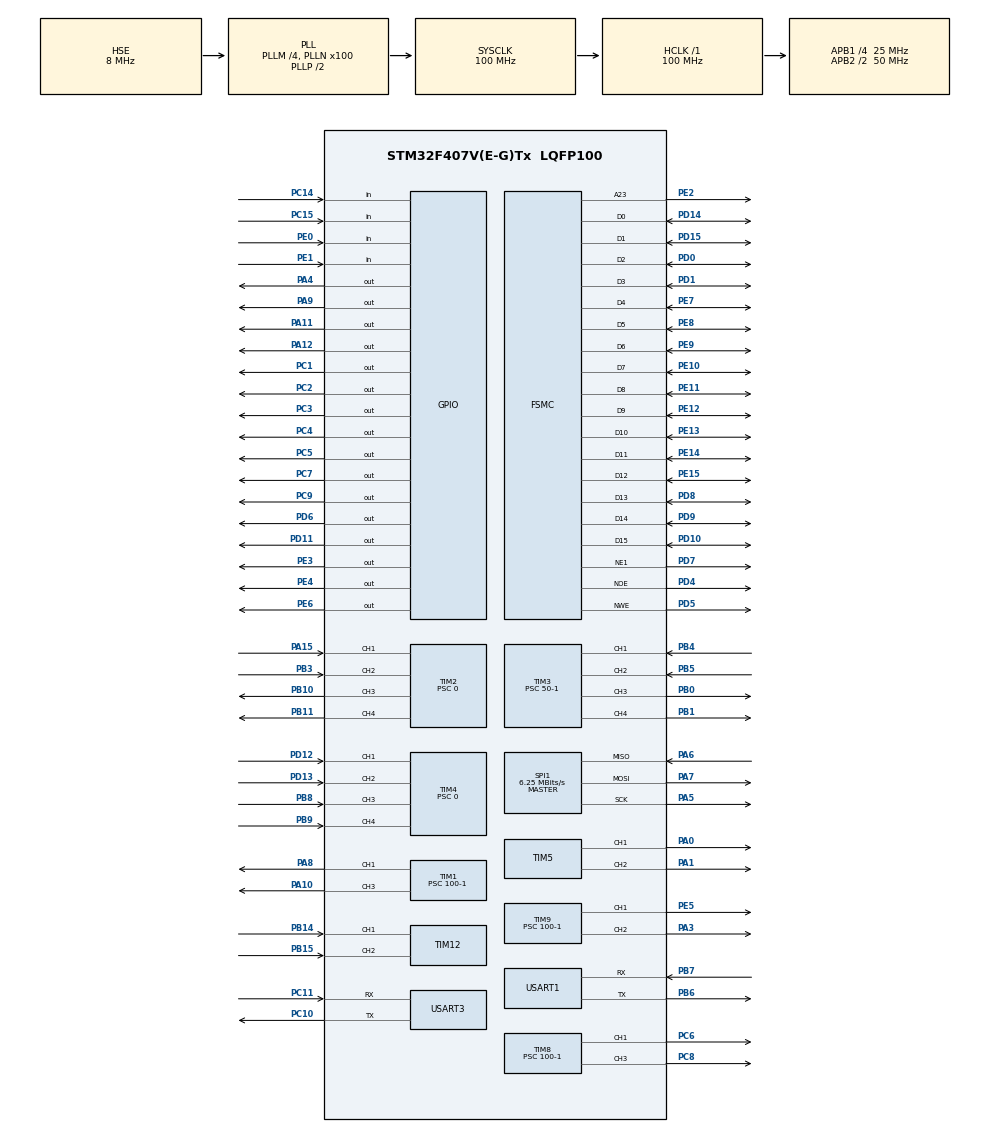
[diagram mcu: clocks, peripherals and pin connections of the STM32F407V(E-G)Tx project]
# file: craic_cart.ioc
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Dma.Request0=USART3_RX
Dma.Request1=USART1_RX
Dma.USART1_RX.1.Direction=DMA_PERIPH_TO_MEMORY
Dma.USART1_RX.1.FIFOMode=DMA_FIFOMODE_DISABLE
Dma.USART1_RX.1.Instance=DMA2_Stream2
Dma.USART1_RX.1.MemDataAlignment=DMA_MDATAALIGN_BYTE
Dma.USART1_RX.1.MemInc=DMA_MINC_ENABLE
Dma.USART1_RX.1.Mode=DMA_NORMAL
Dma.USART1_RX.1.PeriphDataAlignment=DMA_PDATAALIGN_BYTE
Dma.USART1_RX.1.PeriphInc=DMA_PINC_DISABLE
Dma.USART1_RX.1.Priority=DMA_PRIORITY_LOW
Dma.USART3_RX.0.Direction=DMA_PERIPH_TO_MEMORY
Dma.USART3_RX.0.FIFOMode=DMA_FIFOMODE_DISABLE
Dma.USART3_RX.0.Instance=DMA1_Stream1
Dma.USART3_RX.0.MemDataAlignment=DMA_MDATAALIGN_BYTE
Dma.USART3_RX.0.MemInc=DMA_MINC_ENABLE
Dma.USART3_RX.0.Mode=DMA_NORMAL
Dma.USART3_RX.0.PeriphDataAlignment=DMA_PDATAALIGN_BYTE
Dma.USART3_RX.0.PeriphInc=DMA_PINC_DISABLE
Dma.USART3_RX.0.Priority=DMA_PRIORITY_LOW
Mcu.Family=STM32F4
Mcu.Name=STM32F407V(E-G)Tx
Mcu.Package=LQFP100
NVIC.DMA1_Stream1_IRQn=true\:0\:0\:false\:false\:true\:false\:true
NVIC.DMA2_Stream2_IRQn=true\:0\:0\:false\:false\:true\:false\:true
NVIC.PriorityGroup=NVIC_PRIORITYGROUP_4
NVIC.TIM1_TRG_COM_TIM11_IRQn=true\:0\:0\:false\:false\:true\:true\:true
NVIC.TIM1_UP_TIM10_IRQn=true\:0\:0\:false\:false\:true\:true\:true
NVIC.TIM2_IRQn=true\:0\:0\:false\:false\:true\:true\:true
NVIC.TIM3_IRQn=true\:0\:0\:false\:false\:true\:true\:true
NVIC.TIM4_IRQn=true\:0\:0\:false\:false\:true\:true\:true
NVIC.TIM6_DAC_IRQn=true\:0\:0\:false\:false\:true\:true\:true
NVIC.TIM7_IRQn=true\:1\:0\:true\:false\:true\:true\:true
NVIC.TIM8_BRK_TIM12_IRQn=true\:0\:0\:false\:false\:true\:true\:true
NVIC.TIM8_TRG_COM_TIM14_IRQn=true\:2\:0\:true\:false\:true\:true\:true
NVIC.TIM8_UP_TIM13_IRQn=true\:1\:0\:true\:false\:true\:true\:true
NVIC.USART1_IRQn=true\:0\:0\:false\:false\:true\:true\:true
NVIC.USART3_IRQn=true\:0\:0\:false\:false\:true\:true\:true
PA0-WKUP.Signal=S_TIM5_CH1
PA1.Signal=S_TIM5_CH2
PA10.Signal=S_TIM1_CH3
PA11.Signal=GPIO_Output
PA12.GPIO_ModeDefaultOutputPP=GPIO_MODE_OUTPUT_PP
PA12.GPIO_PuPd=GPIO_PULLDOWN
PA12.GPIO_Speed=GPIO_SPEED_FREQ_VERY_HIGH
PA12.PinState=GPIO_PIN_RESET
PA12.Signal=GPIO_Output
PA13.Mode=Serial_Wire
PA13.Signal=SYS_JTMS-SWDIO
PA14.Mode=Serial_Wire
PA14.Signal=SYS_JTCK-SWCLK
PA15.Signal=S_TIM2_CH1_ETR
PA3.Signal=S_TIM9_CH2
PA4.Signal=GPIO_Output
PA5.Mode=Full_Duplex_Master
PA5.Signal=SPI1_SCK
PA6.Mode=Full_Duplex_Master
PA6.Signal=SPI1_MISO
PA7.Mode=Full_Duplex_Master
PA7.Signal=SPI1_MOSI
PA8.Signal=S_TIM1_CH1
PA9.Signal=GPIO_Output
PB0.Signal=S_TIM3_CH3
PB1.Signal=S_TIM3_CH4
PB10.Signal=S_TIM2_CH3
PB11.Signal=S_TIM2_CH4
PB14.Signal=S_TIM12_CH1
PB15.Signal=S_TIM12_CH2
PB3.Signal=S_TIM2_CH2
PB4.Signal=S_TIM3_CH1
PB5.Signal=S_TIM3_CH2
PB6.Mode=Asynchronous
PB6.Signal=USART1_TX
PB7.Mode=Asynchronous
PB7.Signal=USART1_RX
PB8.Signal=S_TIM4_CH3
PB9.Signal=S_TIM4_CH4
PC1.Signal=GPIO_Output
PC10.Mode=Asynchronous
PC10.Signal=USART3_TX
PC11.Mode=Asynchronous
PC11.Signal=USART3_RX
PC14-OSC32_IN.GPIO_Mode=GPIO_MODE_INPUT
PC14-OSC32_IN.GPIO_PuPd=GPIO_PULLUP
PC14-OSC32_IN.Signal=GPIO_Input
PC15-OSC32_OUT.GPIO_Mode=GPIO_MODE_INPUT
PC15-OSC32_OUT.GPIO_PuPd=GPIO_PULLUP
PC15-OSC32_OUT.Signal=GPIO_Input
PC2.Signal=GPIO_Output
PC3.Signal=GPIO_Output
PC4.GPIO_ModeDefaultOutputPP=GPIO_MODE_OUTPUT_PP
PC4.GPIO_PuPd=GPIO_NOPULL
PC4.GPIO_Speed=GPIO_SPEED_FREQ_MEDIUM
PC4.PinState=GPIO_PIN_SET
PC4.Signal=GPIO_Output
PC5.GPIO_ModeDefaultOutputPP=GPIO_MODE_OUTPUT_PP
PC5.GPIO_PuPd=GPIO_NOPULL
PC5.GPIO_Speed=GPIO_SPEED_FREQ_MEDIUM
PC5.PinState=GPIO_PIN_SET
PC5.Signal=GPIO_Output
PC6.Signal=S_TIM8_CH1
PC7.Signal=GPIO_Output
PC8.Signal=S_TIM8_CH3
PC9.Signal=GPIO_Output
PD0.Mode=16b-d1
PD0.Signal=FSMC_D2
PD1.Mode=16b-d1
PD1.Signal=FSMC_D3
PD10.Mode=16b-d1
PD10.Signal=FSMC_D15
PD11.Signal=GPIO_Output
PD12.Signal=S_TIM4_CH1
PD13.Signal=S_TIM4_CH2
PD14.Mode=16b-d1
PD14.Signal=FSMC_D0
PD15.Mode=16b-d1
PD15.Signal=FSMC_D1
PD4.Mode=Lcd1
PD4.Signal=FSMC_NOE
PD5.Mode=Lcd1
PD5.Signal=FSMC_NWE
PD6.GPIO_PuPd=GPIO_PULLDOWN
PD6.GPIO_Speed=GPIO_SPEED_FREQ_VERY_HIGH
PD6.Signal=GPIO_Output
PD7.Mode=NorPsramChipSelect1_1
PD7.Signal=FSMC_NE1
PD8.Mode=16b-d1
PD8.Signal=FSMC_D13
PD9.Mode=16b-d1
PD9.Signal=FSMC_D14
PE0.GPIO_Mode=GPIO_MODE_INPUT
PE0.GPIO_PuPd=GPIO_PULLUP
PE0.Signal=GPIO_Input
PE1.GPIO_Mode=GPIO_MODE_INPUT
PE1.GPIO_PuPd=GPIO_PULLUP
PE1.Signal=GPIO_Input
PE10.Mode=16b-d1
PE10.Signal=FSMC_D7
PE11.Mode=16b-d1
PE11.Signal=FSMC_D8
PE12.Mode=16b-d1
PE12.Signal=FSMC_D9
PE13.Mode=16b-d1
PE13.Signal=FSMC_D10
PE14.Mode=16b-d1
PE14.Signal=FSMC_D11
PE15.Mode=16b-d1
PE15.Signal=FSMC_D12
PE2.Mode=A23_1
PE2.Signal=FSMC_A23
PE3.GPIO_ModeDefaultOutputPP=GPIO_MODE_OUTPUT_OD
PE3.GPIO_PuPd=GPIO_PULLUP
PE3.GPIO_Speed=GPIO_SPEED_FREQ_LOW
PE3.PinState=GPIO_PIN_RESET
PE3.Signal=GPIO_Output
PE4.GPIO_ModeDefaultOutputPP=GPIO_MODE_OUTPUT_OD
PE4.GPIO_PuPd=GPIO_PULLUP
PE4.GPIO_Speed=GPIO_SPEED_FREQ_LOW
PE4.PinState=GPIO_PIN_RESET
PE4.Signal=GPIO_Output
PE5.Signal=S_TIM9_CH1
PE6.Signal=GPIO_Output
PE7.Mode=16b-d1
PE7.Signal=FSMC_D4
PE8.Mode=16b-d1
PE8.Signal=FSMC_D5
PE9.Mode=16b-d1
PE9.Signal=FSMC_D6
PH0-OSC_IN.Mode=HSE-External-Oscillator
PH0-OSC_IN.Signal=RCC_OSC_IN
PH1-OSC_OUT.Mode=HSE-External-Oscillator
PH1-OSC_OUT.Signal=RCC_OSC_OUT
ProjectManager.HeapSize=0x200
ProjectManager.StackSize=0x400
ProjectManager.TargetToolchain=MDK-ARM V5.27
RCC.48MHZClocksFreq_Value=50000000
RCC.AHBFreq_Value=100000000
RCC.APB1CLKDivider=RCC_HCLK_DIV4
RCC.APB1Freq_Value=25000000
RCC.APB1TimFreq_Value=50000000
RCC.APB2CLKDivider=RCC_HCLK_DIV2
RCC.APB2Freq_Value=50000000
RCC.APB2TimFreq_Value=100000000
RCC.CortexFreq_Value=100000000
RCC.HCLKFreq_Value=100000000
RCC.HSE_VALUE=8000000
RCC.HSI_VALUE=16000000
RCC.LSE_VALUE=32768
RCC.PLLM=4
RCC.PLLN=100
RCC.PLLSourceVirtual=RCC_PLLSOURCE_HSE
RCC.SYSCLKFreq_VALUE=100000000
RCC.SYSCLKSource=RCC_SYSCLKSOURCE_PLLCLK
RCC.VCOOutputFreq_Value=200000000
SH.S_TIM12_CH1.0=TIM12_CH1,Input_Capture1_from_TI1
SH.S_TIM12_CH2.0=TIM12_CH2,Input_Capture2_from_TI2
SH.S_TIM1_CH1.0=TIM1_CH1,PWM Generation1 CH1
SH.S_TIM1_CH3.0=TIM1_CH3,PWM Generation3 CH3
SH.S_TIM2_CH1_ETR.0=TIM2_CH1,Input_Capture1_from_TI1
SH.S_TIM2_CH2.0=TIM2_CH2,Input_Capture2_from_TI2
SH.S_TIM2_CH3.0=TIM2_CH3,PWM Generation3 CH3
SH.S_TIM2_CH4.0=TIM2_CH4,PWM Generation4 CH4
SH.S_TIM3_CH1.0=TIM3_CH1,Input_Capture1_from_TI1
SH.S_TIM3_CH2.0=TIM3_CH2,Input_Capture2_from_TI2
SH.S_TIM3_CH3.0=TIM3_CH3,PWM Generation3 CH3
SH.S_TIM3_CH4.0=TIM3_CH4,PWM Generation4 CH4
SH.S_TIM4_CH1.0=TIM4_CH1,Input_Capture1_from_TI1
SH.S_TIM4_CH2.0=TIM4_CH2,Input_Capture2_from_TI2
SH.S_TIM4_CH3.0=TIM4_CH3,Input_Capture3_from_TI3
SH.S_TIM4_CH4.0=TIM4_CH4,Input_Capture4_from_TI4
SH.S_TIM5_CH1.0=TIM5_CH1,PWM Generation1 CH1
SH.S_TIM5_CH2.0=TIM5_CH2,PWM Generation2 CH2
SH.S_TIM8_CH1.0=TIM8_CH1,PWM Generation1 CH1
SH.S_TIM8_CH3.0=TIM8_CH3,PWM Generation3 CH3
SH.S_TIM9_CH1.0=TIM9_CH1,PWM Generation1 CH1
SH.S_TIM9_CH2.0=TIM9_CH2,PWM Generation2 CH2
SPI1.BaudRatePrescaler=SPI_BAUDRATEPRESCALER_8
SPI1.CalculateBaudRate=6.25 MBits/s
SPI1.Direction=SPI_DIRECTION_2LINES
SPI1.Mode=SPI_MODE_MASTER
SPI1.VirtualType=VM_MASTER
TIM1.Channel-PWM\ Generation1\ CH1=TIM_CHANNEL_1
TIM1.Channel-PWM\ Generation3\ CH3=TIM_CHANNEL_3
TIM1.Prescaler=100-1
TIM10.Period=20000-1
TIM10.Prescaler=100-1
TIM11.Period=200-1
TIM11.Prescaler=100-1
TIM12.Channel-Input_Capture1_from_TI1=TIM_CHANNEL_1
TIM12.Channel-Input_Capture2_from_TI2=TIM_CHANNEL_2
TIM12.ICFilter_CH1=6
TIM12.ICFilter_CH2=6
TIM13.Period=1000-1
TIM13.Prescaler=100-1
TIM14.Period=1000-1
TIM14.Prescaler=100-1
TIM2.Channel-Input_Capture1_from_TI1=TIM_CHANNEL_1
TIM2.Channel-Input_Capture2_from_TI2=TIM_CHANNEL_2
TIM2.Channel-PWM\ Generation3\ CH3=TIM_CHANNEL_3
TIM2.Channel-PWM\ Generation4\ CH4=TIM_CHANNEL_4
TIM2.ICFilter_CH1=6
TIM2.ICFilter_CH2=6
TIM2.Prescaler=0
TIM3.Channel-Input_Capture1_from_TI1=TIM_CHANNEL_1
TIM3.Channel-Input_Capture2_from_TI2=TIM_CHANNEL_2
TIM3.Channel-PWM\ Generation3\ CH3=TIM_CHANNEL_3
TIM3.Channel-PWM\ Generation4\ CH4=TIM_CHANNEL_4
TIM3.ICFilter_CH1=6
TIM3.ICFilter_CH2=6
TIM3.Prescaler=50-1
TIM4.Channel-Input_Capture1_from_TI1=TIM_CHANNEL_1
TIM4.Channel-Input_Capture2_from_TI2=TIM_CHANNEL_2
TIM4.Channel-Input_Capture3_from_TI3=TIM_CHANNEL_3
TIM4.Channel-Input_Capture4_from_TI4=TIM_CHANNEL_4
TIM4.ICFilter_CH1=6
TIM4.ICFilter_CH2=6
TIM4.ICFilter_CH3=6
TIM4.ICFilter_CH4=6
TIM4.Prescaler=0
TIM5.Channel-PWM\ Generation1\ CH1=TIM_CHANNEL_1
TIM5.Channel-PWM\ Generation2\ CH2=TIM_CHANNEL_2
TIM6.Period=10000-1
TIM6.Prescaler=50-1
TIM7.Period=65535
TIM7.Prescaler=100-1
TIM8.Channel-PWM\ Generation1\ CH1=TIM_CHANNEL_1
TIM8.Channel-PWM\ Generation3\ CH3=TIM_CHANNEL_3
TIM8.Prescaler=100-1
TIM9.Channel-PWM\ Generation1\ CH1=TIM_CHANNEL_1
TIM9.Channel-PWM\ Generation2\ CH2=TIM_CHANNEL_2
TIM9.Prescaler=100-1
USART1.VirtualMode=VM_ASYNC
USART3.VirtualMode=VM_ASYNC
VP_TIM10_VS_ClockSourceINT.Mode=Enable_Timer
VP_TIM11_VS_ClockSourceINT.Mode=Enable_Timer
VP_TIM13_VS_ClockSourceINT.Mode=Enable_Timer
VP_TIM14_VS_ClockSourceINT.Mode=Enable_Timer
VP_TIM1_VS_ClockSourceINT.Mode=Internal
VP_TIM2_VS_ClockSourceINT.Mode=Internal
VP_TIM3_VS_ClockSourceINT.Mode=Internal
VP_TIM5_VS_ClockSourceINT.Mode=Internal
VP_TIM6_VS_ClockSourceINT.Mode=Enable_Timer
VP_TIM7_VS_ClockSourceINT.Mode=Enable_Timer
VP_TIM8_VS_ClockSourceINT.Mode=Internal
VP_TIM9_VS_ClockSourceINT.Mode=Internal
board=custom

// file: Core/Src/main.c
/* USER CODE BEGIN Header */
/**
  ******************************************************************************
  * @file           : main.c
  * @brief          : Main program body
  ******************************************************************************
  * @attention
  *
  * <h2><center>&copy; Copyright (c) 2024 STMicroelectronics.
  * All rights reserved.</center></h2>
  *
  * This software component is licensed by ST under BSD 3-Clause license,
  * the "License"; You may not use this file except in compliance with the
  * License. You may obtain a copy of the License at:
  *                        opensource.org/licenses/BSD-3-Clause
  *
  ******************************************************************************
  */
/* USER CODE END Header */
#include "main.h"
#include "dma.h"
#include "spi.h"
#include "tim.h"
#include "usart.h"
#include "gpio.h"
#include "fsmc.h"

/* USER CODE BEGIN Includes */
#include "beep.h"
#include "key.h"
#include "pwm.h"
#include "led.h"
#include "encoder.h"
#include "motor.h"
#include "stdio.h"
#include "communication.h"
#include "servo.h"
#include "lcd.h"
/* USER CODE END Includes */

/* USER CODE BEGIN PV */
__IO uint32_t lcdTick = 0;
char text[30];
/* USER CODE END PV */

void SystemClock_Config(void);

/* USER CODE BEGIN 0 */
void lcd_proc(void)
{
	if(uwTick-lcdTick<50)return;
	sprintf(text,"Hello!");
	lcd_show_string(0,0,320,32,32,text,BLACK);
}
void key_proc(void)
{
	if(keys[0].key_flag == 1)
	{
		//Beep_ON
		//distance_target_new += 100;
		//Move_speed = 10;
		printf("1\n");
		keys[0].key_flag = 0;
	}
	if(keys[1].key_flag == 1)
	{
		//distance_target_new -= 100;
		//Beep_OFF
		//Move_speed = -10;
		printf("2\n");
		keys[1].key_flag = 0;
	}
	if(keys[2].key_flag == 1)
	{
		//distance_target = distance_target_new;
		//Move_speed = 0;
		printf("3\n");
		keys[2].key_flag = 0;
	}
	if(keys[3].key_flag == 1)
	{
		printf("4\n");
		Beep_Toggle
		keys[3].key_flag = 0;
	}
}
int fputc(int ch, FILE *f)
{
  /* Your implementation of fputc(). */
	HAL_UART_Transmit(&huart3, (uint8_t *)&ch, 1, 50);
  return ch;
}

/* USER CODE END 0 */

int main(void)
{

  /* MCU Configuration--------------------------------------------------------*/

  /* Reset of all peripherals, Initializes the Flash interface and the Systick. */
  HAL_Init();

  /* Configure the system clock */
  SystemClock_Config();

  /* Initialize all configured peripherals */
  MX_GPIO_Init();
  MX_DMA_Init();
  MX_TIM1_Init();
  MX_TIM2_Init();
  MX_TIM3_Init();
  MX_TIM4_Init();
  MX_TIM8_Init();
  MX_TIM9_Init();
  MX_TIM12_Init();
  MX_USART3_UART_Init();
  MX_SPI1_Init();
  MX_TIM5_Init();
  MX_TIM6_Init();
  MX_TIM7_Init();
  MX_TIM10_Init();
  MX_TIM11_Init();
  MX_USART1_UART_Init();
  MX_FSMC_Init();
  MX_TIM13_Init();
  MX_TIM14_Init();
  /* USER CODE BEGIN 2 */
	//printf("Hello\r\n");
	htim11.Instance->ARR = 65535;
	communication_init();
	lcd_init();
	motor_init();
	encoder_init();
	servo_init();
	fan_init();
	FAN_OFF
	HAL_TIM_Base_Start_IT(&htim6);
	HAL_TIM_Base_Start_IT(&htim14);
	HAL_TIM_Base_Start_IT(&htim10);
	//HAL_TIM_Base_Start_IT(&htim13);
	//led_control(red);
//	pwm_init();
  /* USER CODE END 2 */

  /* Infinite loop */
  while (1)
  {

    /* USER CODE BEGIN 3 */
		key_proc();
		lcd_proc();
  }
  /* USER CODE END 3 */
}

void SystemClock_Config(void)
{
  RCC_OscInitTypeDef RCC_OscInitStruct = {0};
  RCC_ClkInitTypeDef RCC_ClkInitStruct = {0};

  /** Configure the main internal regulator output voltage
  */
  __HAL_RCC_PWR_CLK_ENABLE();
  __HAL_PWR_VOLTAGESCALING_CONFIG(PWR_REGULATOR_VOLTAGE_SCALE1);
  /** Initializes the RCC Oscillators according to the specified parameters
  * in the RCC_OscInitTypeDef structure.
  */
  RCC_OscInitStruct.OscillatorType = RCC_OSCILLATORTYPE_HSE;
  RCC_OscInitStruct.HSEState = RCC_HSE_ON;
  RCC_OscInitStruct.PLL.PLLState = RCC_PLL_ON;
  RCC_OscInitStruct.PLL.PLLSource = RCC_PLLSOURCE_HSE;
  RCC_OscInitStruct.PLL.PLLM = 4;
  RCC_OscInitStruct.PLL.PLLN = 100;
  RCC_OscInitStruct.PLL.PLLP = RCC_PLLP_DIV2;
  RCC_OscInitStruct.PLL.PLLQ = 4;
  if (HAL_RCC_OscConfig(&RCC_OscInitStruct) != HAL_OK)
  {
    Error_Handler();
  }
  /** Initializes the CPU, AHB and APB buses clocks
  */
  RCC_ClkInitStruct.ClockType = RCC_CLOCKTYPE_HCLK|RCC_CLOCKTYPE_SYSCLK
                              |RCC_CLOCKTYPE_PCLK1|RCC_CLOCKTYPE_PCLK2;
  RCC_ClkInitStruct.SYSCLKSource = RCC_SYSCLKSOURCE_PLLCLK;
  RCC_ClkInitStruct.AHBCLKDivider = RCC_SYSCLK_DIV1;
  RCC_ClkInitStruct.APB1CLKDivider = RCC_HCLK_DIV4;
  RCC_ClkInitStruct.APB2CLKDivider = RCC_HCLK_DIV2;

  if (HAL_RCC_ClockConfig(&RCC_ClkInitStruct, FLASH_LATENCY_3) != HAL_OK)
  {
    Error_Handler();
  }
}

void Error_Handler(void)
{
  __disable_irq();
  while (1)
  {
  }
}

/************************ (C) COPYRIGHT STMicroelectronics *****END OF FILE****/
